AUTOSAR XML (schema 00050)
package /Components
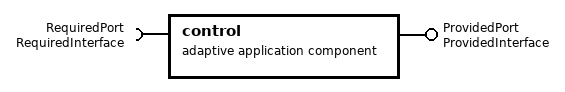
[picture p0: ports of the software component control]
  adaptive application sw component type control
    require port RequiredPort: required-com-specs=[data-element=LKAS, data-element=AEB], required-interface=RequiredInterface
    provide port ProvidedPort: provided-interface=ProvidedInterface
